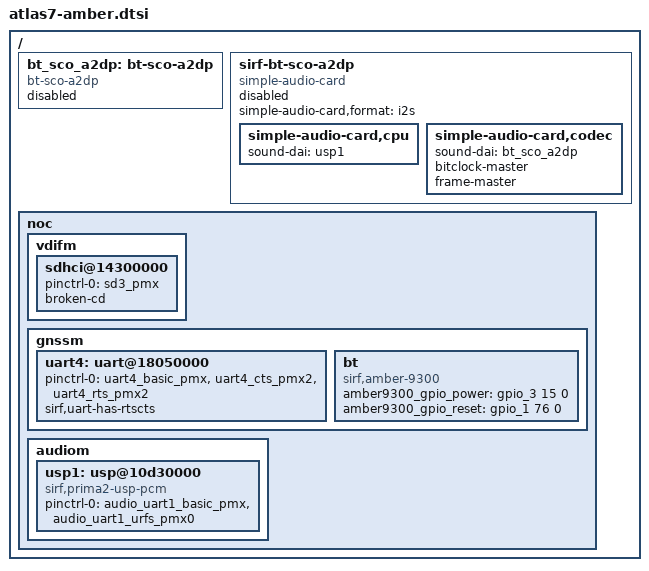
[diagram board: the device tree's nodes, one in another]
/*
 * DTS file for CSR SiRFatlas7 SoC External Amber Chip
 *
 * Copyright (c) 2015-2016, The Linux Foundation. All rights reserved.
 *
 * This program is free software; you can redistribute it and/or modify
 * it under the terms of the GNU General Public License version 2 and
 * only version 2 as published by the Free Software Foundation.
 *
 * This program is distributed in the hope that it will be useful,
 * but WITHOUT ANY WARRANTY; without even the implied warranty of
 * MERCHANTABILITY or FITNESS FOR A PARTICULAR PURPOSE.  See the
 * GNU General Public License for more details.
 */

/ {
	bt_sco_a2dp: bt-sco-a2dp {
		#sound-dai-cells = <0>;
		compatible = "bt-sco-a2dp";
		status = "disabled";
	};
/*
 * FIXME
 * Now pcm interface is used in android while i2s interface is used in linux
 * It is necessay to drop this workaround after i2s interface is used in android
 */
	sirf-bt-sco-a2dp {
		status = "disabled";
		compatible = "simple-audio-card";
		simple-audio-card,format = "i2s";
		simple-audio-card,cpu {
			sound-dai = <&usp1>;
		};
		simple-audio-card,codec {
			sound-dai = <&bt_sco_a2dp>;
			bitclock-master;
			frame-master;
		};
	};
	noc {
		vdifm {
			sdhci@14300000 {
				status = "okay";
				pinctrl-names = "default";
				pinctrl-0 = <&sd3_pmx>;
				broken-cd;
			};
		};
		gnssm {
			uart4: uart@18050000 {
				status = "okay";
				pinctrl-0 = <&uart4_basic_pmx
						&uart4_cts_pmx2
						&uart4_rts_pmx2>;
				pinctrl-names = "default";
				sirf,uart-has-rtscts;
			};
			bt {
				compatible = "sirf,amber-9300";
				amber9300_gpio_power = <&gpio_3 15 0>;
				amber9300_gpio_reset = <&gpio_1 76 0>;
			};
		};
		audiom {
			usp1: usp@10d30000 {
				status = "okay";
				#sound-dai-cells = <0>;
				compatible = "sirf,prima2-usp-pcm";
				pinctrl-names = "default";
				pinctrl-0 = <&audio_uart1_basic_pmx
						&audio_uart1_urfs_pmx0>;
			};
		};
	};
};
